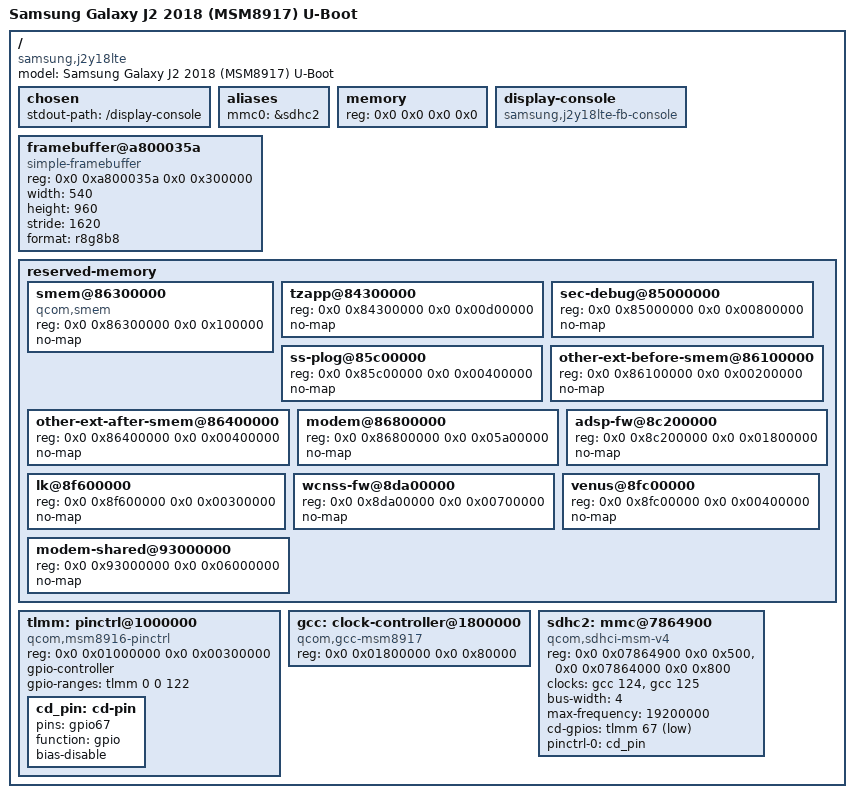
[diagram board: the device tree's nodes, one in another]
/dts-v1/;

/ {
	model = "Samsung Galaxy J2 2018 (MSM8917) U-Boot";
	compatible = "samsung,j2y18lte", "qcom,msm8917";
	#address-cells = <2>;
	#size-cells = <2>;

	chosen {
		stdout-path = "/display-console";
	};

	aliases {
		mmc0 = &sdhc2;
	};

	/* Let Qualcomm's SMEM usable-RAM table provide the full safe RAM map. */
	memory {
		device_type = "memory";
		reg = <0x0 0x0 0x0 0x0>;
	};

	display-console {
		compatible = "samsung,j2y18lte-fb-console";
		status = "okay";
		bootph-all;
	};

	/* The display controller is already scanning this S-Boot framebuffer. */
	framebuffer@a800035a {
		compatible = "simple-framebuffer";
		reg = <0x0 0xa800035a 0x0 0x300000>;
		width = <540>;
		height = <960>;
		stride = <1620>;
		format = "r8g8b8";
		status = "okay";
	};

	/* Needed by Snapdragon DRAM discovery when the internal FDT omits /memory. */
	reserved-memory {
		#address-cells = <2>;
		#size-cells = <2>;
		ranges;

		smem@86300000 {
			compatible = "qcom,smem";
			reg = <0x0 0x86300000 0x0 0x100000>;
			no-map;
		};

		/* Match the phone DT carveouts so U-Boot does not touch firmware RAM. */
		tzapp@84300000 {
			reg = <0x0 0x84300000 0x0 0x00d00000>;
			no-map;
		};

		sec-debug@85000000 {
			reg = <0x0 0x85000000 0x0 0x00800000>;
			no-map;
		};

		ss-plog@85c00000 {
			reg = <0x0 0x85c00000 0x0 0x00400000>;
			no-map;
		};

		other-ext-before-smem@86100000 {
			reg = <0x0 0x86100000 0x0 0x00200000>;
			no-map;
		};

		other-ext-after-smem@86400000 {
			reg = <0x0 0x86400000 0x0 0x00400000>;
			no-map;
		};

		modem@86800000 {
			reg = <0x0 0x86800000 0x0 0x05a00000>;
			no-map;
		};

		adsp-fw@8c200000 {
			reg = <0x0 0x8c200000 0x0 0x01800000>;
			no-map;
		};

		lk@8f600000 {
			reg = <0x0 0x8f600000 0x0 0x00300000>;
			no-map;
		};

		wcnss-fw@8da00000 {
			reg = <0x0 0x8da00000 0x0 0x00700000>;
			no-map;
		};

		venus@8fc00000 {
			reg = <0x0 0x8fc00000 0x0 0x00400000>;
			no-map;
		};

		modem-shared@93000000 {
			reg = <0x0 0x93000000 0x0 0x06000000>;
			no-map;
		};
	};

	/* MSM8917 SDCC2 only. SDCC1 (eMMC) is intentionally absent. */
	tlmm: pinctrl@1000000 {
		compatible = "qcom,msm8916-pinctrl";
		reg = <0x0 0x01000000 0x0 0x00300000>;
		gpio-controller;
		#gpio-cells = <2>;
		gpio-ranges = <&tlmm 0 0 122>;

		/* SDHC2 card detect: GPIO67, active low. */
		cd_pin: cd-pin {
			pins = "gpio67";
			function = "gpio";
			bias-disable;
		};
	};

	gcc: clock-controller@1800000 {
		compatible = "qcom,gcc-msm8917";
		reg = <0x0 0x01800000 0x0 0x80000>;
		#clock-cells = <1>;
	};

	sdhc2: mmc@7864900 {
		compatible = "qcom,sdhci-msm-v4";
		reg = <0x0 0x07864900 0x0 0x500>,
		      <0x0 0x07864000 0x0 0x800>;
		reg-names = "hc", "core";
		clocks = <&gcc 124>, <&gcc 125>;
		clock-names = "iface", "core";
		bus-width = <4>;
		/* Keep first bring-up at the 19.2 MHz XO rate. */
		max-frequency = <19200000>;
		cd-gpios = <&tlmm 67 1>;
		pinctrl-names = "default";
		pinctrl-0 = <&cd_pin>;
		status = "okay";
	};
};
